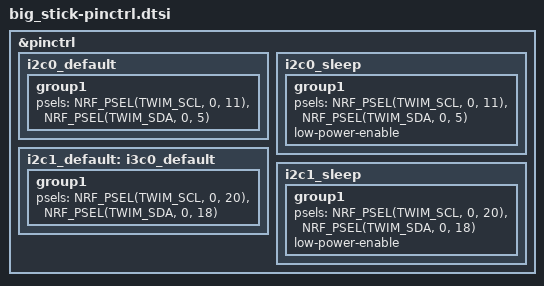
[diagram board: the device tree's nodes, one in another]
&pinctrl {
	i2c0_default: i2c0_default {
		group1 {
			psels = <NRF_PSEL(TWIM_SCL, 0, 11)>,
				<NRF_PSEL(TWIM_SDA, 0, 5)>;
		};
	};

	i2c0_sleep: i2c0_sleep {
		group1 {
			psels = <NRF_PSEL(TWIM_SCL, 0, 11)>,
				<NRF_PSEL(TWIM_SDA, 0, 5)>;
			low-power-enable;
		};
	};

	i2c1_default: i3c0_default {
		group1 {
			psels = <NRF_PSEL(TWIM_SCL, 0, 20)>,
				<NRF_PSEL(TWIM_SDA, 0, 18)>;
		};
	};

	i2c1_sleep: i2c1_sleep {
		group1 {
			psels = <NRF_PSEL(TWIM_SCL, 0, 20)>,
				<NRF_PSEL(TWIM_SDA, 0, 18)>;
			low-power-enable;
		};
	};
};
